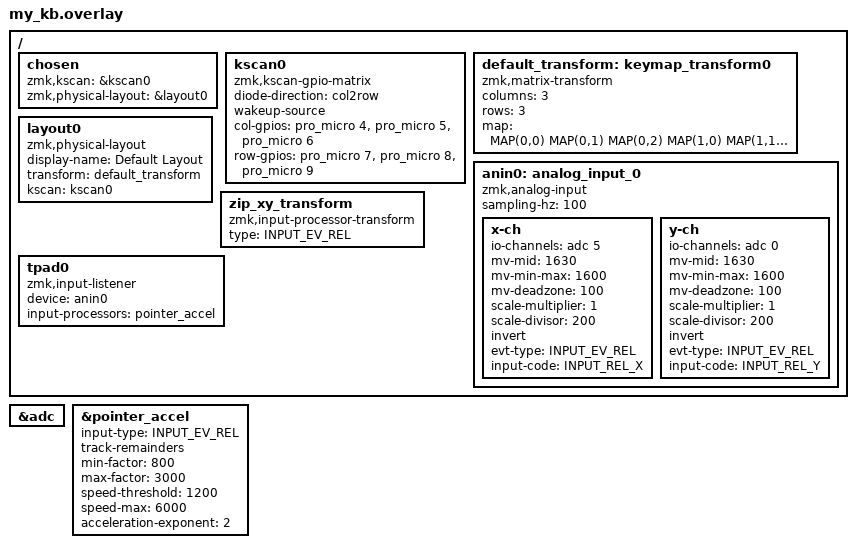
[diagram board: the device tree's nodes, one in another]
#include <dt-bindings/zmk/mouse.h>
#include <dt-bindings/zmk/matrix_transform.h>
#include <dt-bindings/zmk/keys.h>
#include <zephyr/dt-bindings/input/input-event-codes.h>
#include <dt-bindings/zmk/pointing.h>

// マトリックス定義の衝突回避
#define MAP(row, col) (row * 3 + col)

#include <input/processors.dtsi>
#include <behaviors/input_gestures_accel.dtsi>

&adc {
    status = "okay";
};

/ {
    chosen {
        zmk,kscan = &kscan0;
        zmk,physical-layout = &layout0;
    };

    kscan0: kscan0 {
        compatible = "zmk,kscan-gpio-matrix";
        diode-direction = "col2row";
        wakeup-source;
        col-gpios = <&pro_micro 4 GPIO_ACTIVE_HIGH>, <&pro_micro 5 GPIO_ACTIVE_HIGH>, <&pro_micro 6 GPIO_ACTIVE_HIGH>;
        row-gpios = <&pro_micro 7 (GPIO_ACTIVE_HIGH | GPIO_PULL_DOWN)>, <&pro_micro 8 (GPIO_ACTIVE_HIGH | GPIO_PULL_DOWN)>, <&pro_micro 9 (GPIO_ACTIVE_HIGH | GPIO_PULL_DOWN)>;
    };

    default_transform: keymap_transform0 {
        compatible = "zmk,matrix-transform";
        columns = <3>;
        rows = <3>;
        map = <
            MAP(0,0) MAP(0,1) MAP(0,2)
            MAP(1,0) MAP(1,1) MAP(1,2)
            MAP(2,0) MAP(2,1) MAP(2,2)
        >;
    };

    layout0: layout0 {
        compatible = "zmk,physical-layout";
        display-name = "Default Layout";
        transform = <&default_transform>;
        kscan = <&kscan0>;
    };

    anin0: analog_input_0 {
        compatible = "zmk,analog-input";
        sampling-hz = <100>;
        x-ch {
            io-channels = <&adc 5>; 
            mv-mid = <1630>;
            mv-min-max = <1600>;
            mv-deadzone = <100>;
            scale-multiplier = <1>;
            scale-divisor = <200>;
            invert;
            evt-type = <INPUT_EV_REL>;
            input-code = <INPUT_REL_X>;
        };
        y-ch {
            io-channels = <&adc 0>; 
            mv-mid = <1630>;
            mv-min-max = <1600>;
            mv-deadzone = <100>;
            scale-multiplier = <1>;
            scale-divisor = <200>;
            invert;
            evt-type = <INPUT_EV_REL>;
            input-code = <INPUT_REL_Y>;
        };
    };

    // --- ここが修正ポイント ---
    zip_xy_transform: zip_xy_transform {
        compatible = "zmk,input-processor-transform";
        #input-processor-cells = <1>;
        type = <INPUT_EV_REL>;
    };

    tpad0: tpad0 {
        compatible = "zmk,input-listener";
        status = "okay";
        device = <&anin0>;
        input-processors 
            = <&pointer_accel>
            ;
    };
};

&pointer_accel {
    input-type = <INPUT_EV_REL>;
    track-remainders;
    min-factor = <800>;
    max-factor = <3000>;
    speed-threshold = <1200>;
    speed-max = <6000>;
    acceleration-exponent = <2>;
};
